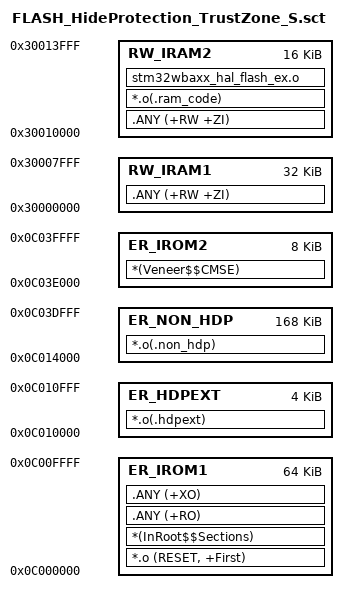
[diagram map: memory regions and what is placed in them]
; *************************************************************
; *** Scatter-Loading Description File generated by uVision ***
; *************************************************************

LR_IROM1 0x0C000000 0x00010000  {    ; load region size_region
  ER_IROM1 0x0C000000 0x00010000  {  ; load address = execution address
   *.o (RESET, +First)
   *(InRoot$$Sections)
   .ANY (+RO)
   .ANY (+XO)
  }

  RW_IRAM1 0x30000000 0x00008000  {  ; RW data
   .ANY (+RW +ZI)
  }
  
  RW_IRAM2 0x30010000 0x00004000  {
   .ANY (+RW +ZI)
   *.o(.ram_code)
   stm32wbaxx_hal_flash_ex.o
  }
}

LR_IROM2 0x0C03E000 0x00002000  {    ; load region size_region
  ER_IROM2 0x0C03E000 0x00002000  {  ; load address = execution address
   *(Veneer$$CMSE)                   ; check with partition.h
  }
}

LR_HDPEXT 0x0C010000 0x00001000  {    ; load region size_region
  ER_HDPEXT 0x0C010000 0x00001000  {
    *.o(.hdpext) 
  }
}
     
LR_NON_HDP 0x0C014000 0x0002A000  {    ; load region size_region
  ER_NON_HDP 0x0C014000 0x0002A000  {
   *.o(.non_hdp)
  }
}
